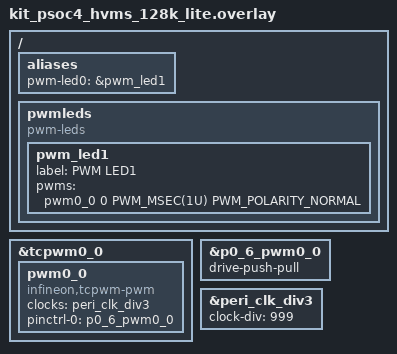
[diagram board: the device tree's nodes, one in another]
/*
 * SPDX-FileCopyrightText: Copyright (c) 2026 Infineon Technologies AG,
 * SPDX-FileCopyrightText: or an affiliate of Infineon Technologies AG. All rights reserved.
 *
 * SPDX-License-Identifier: Apache-2.0
 */

#include <zephyr/dt-bindings/pwm/pwm.h>

/ {
	aliases {
		pwm-led0 = &pwm_led1;
	};

	pwmleds {
		compatible = "pwm-leds";

		pwm_led1: pwm_led1 {
			label = "PWM LED1";
			pwms = <&pwm0_0 0 PWM_MSEC(1U) PWM_POLARITY_NORMAL>;
		};
	};
};

&tcpwm0_0 {
	status = "okay";

	pwm0_0 {
		compatible = "infineon,tcpwm-pwm";
		clocks = <&peri_clk_div3>;
		pinctrl-0 = <&p0_6_pwm0_0>;
		pinctrl-names = "default";
		status = "okay";
	};
};

&p0_6_pwm0_0 {
	drive-push-pull;
};

&peri_clk_div3 {
	clock-div = <999>;
	status = "okay";
};
